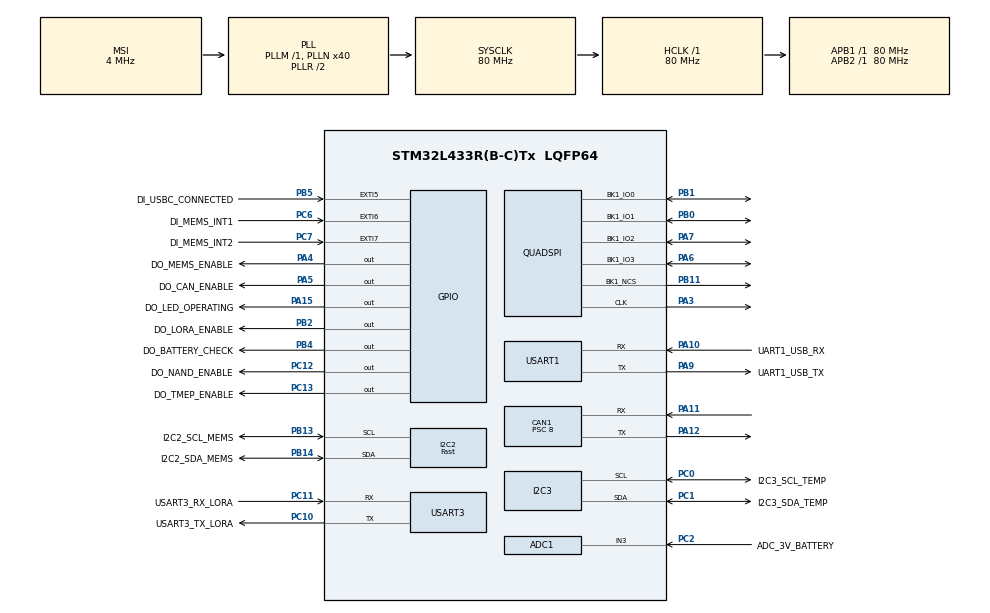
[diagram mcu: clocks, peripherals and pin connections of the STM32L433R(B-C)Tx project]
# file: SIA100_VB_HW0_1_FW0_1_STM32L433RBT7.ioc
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ADC1.ClockPrescaler=ADC_CLOCK_ASYNC_DIV2
ADC1.ContinuousConvMode=DISABLE
ADC1.DMAContinuousRequests=DISABLE
ADC1.EnableRegularConversion=DISABLE
ADC1.master=1
CAN1.ABOM=DISABLE
CAN1.BS1=CAN_BS1_8TQ
CAN1.CalculateBaudRate=1000000
CAN1.CalculateTimeBit=1000
CAN1.CalculateTimeQuantum=100.0
CAN1.Prescaler=8
Dma.Request0=USART1_RX
Dma.Request1=USART3_TX
Dma.Request2=USART3_RX
Dma.USART1_RX.0.Direction=DMA_PERIPH_TO_MEMORY
Dma.USART1_RX.0.Instance=DMA2_Channel7
Dma.USART1_RX.0.MemDataAlignment=DMA_MDATAALIGN_BYTE
Dma.USART1_RX.0.MemInc=DMA_MINC_ENABLE
Dma.USART1_RX.0.Mode=DMA_CIRCULAR
Dma.USART1_RX.0.PeriphDataAlignment=DMA_PDATAALIGN_BYTE
Dma.USART1_RX.0.PeriphInc=DMA_PINC_DISABLE
Dma.USART1_RX.0.Priority=DMA_PRIORITY_LOW
Dma.USART3_RX.2.Direction=DMA_PERIPH_TO_MEMORY
Dma.USART3_RX.2.Instance=DMA1_Channel3
Dma.USART3_RX.2.MemDataAlignment=DMA_MDATAALIGN_BYTE
Dma.USART3_RX.2.MemInc=DMA_MINC_ENABLE
Dma.USART3_RX.2.Mode=DMA_CIRCULAR
Dma.USART3_RX.2.PeriphDataAlignment=DMA_PDATAALIGN_BYTE
Dma.USART3_RX.2.PeriphInc=DMA_PINC_DISABLE
Dma.USART3_RX.2.Priority=DMA_PRIORITY_LOW
Dma.USART3_TX.1.Direction=DMA_MEMORY_TO_PERIPH
Dma.USART3_TX.1.Instance=DMA1_Channel2
Dma.USART3_TX.1.MemDataAlignment=DMA_MDATAALIGN_BYTE
Dma.USART3_TX.1.MemInc=DMA_MINC_ENABLE
Dma.USART3_TX.1.Mode=DMA_NORMAL
Dma.USART3_TX.1.PeriphDataAlignment=DMA_PDATAALIGN_BYTE
Dma.USART3_TX.1.PeriphInc=DMA_PINC_DISABLE
Dma.USART3_TX.1.Priority=DMA_PRIORITY_LOW
I2C2.I2C_Speed_Mode=I2C_Fast
I2C2.Timing=0x00F12981
I2C3.Timing=0x10D19CE4
Mcu.Family=STM32L4
Mcu.Name=STM32L433R(B-C)Tx
Mcu.Package=LQFP64
NVIC.ADC1_IRQn=true\:0\:0\:false\:false\:true\:true\:true\:true
NVIC.CAN1_RX0_IRQn=true\:0\:0\:false\:false\:true\:true\:true\:true
NVIC.CAN1_RX1_IRQn=true\:0\:0\:false\:false\:true\:true\:true\:true
NVIC.DMA1_Channel2_IRQn=true\:0\:0\:false\:false\:true\:false\:true\:true
NVIC.DMA1_Channel3_IRQn=true\:0\:0\:false\:false\:true\:false\:true\:true
NVIC.DMA2_Channel7_IRQn=true\:0\:0\:false\:false\:true\:false\:true\:true
NVIC.EXTI9_5_IRQn=true\:0\:0\:false\:false\:true\:true\:true\:true
NVIC.I2C2_EV_IRQn=true\:0\:0\:false\:false\:true\:true\:true\:true
NVIC.I2C3_EV_IRQn=true\:0\:0\:false\:false\:true\:true\:true\:true
NVIC.PriorityGroup=NVIC_PRIORITYGROUP_4
NVIC.RCC_IRQn=true\:0\:0\:false\:false\:true\:true\:false\:true
NVIC.RTC_WKUP_IRQn=true\:0\:0\:false\:false\:true\:true\:true\:true
NVIC.USART1_IRQn=true\:0\:0\:false\:false\:true\:true\:true\:true
NVIC.USART3_IRQn=true\:0\:0\:false\:false\:true\:true\:true\:true
PA10.GPIO_Label=UART1_USB_RX
PA10.GPIO_PuPd=GPIO_NOPULL
PA10.Mode=Asynchronous
PA10.Signal=USART1_RX
PA11.GPIO_PuPd=GPIO_PULLUP
PA11.Mode=CAN_Activate
PA11.Signal=CAN1_RX
PA12.GPIO_PuPd=GPIO_PULLUP
PA12.Mode=CAN_Activate
PA12.Signal=CAN1_TX
PA13\ (JTMS-SWDIO).Mode=Serial_Wire
PA13\ (JTMS-SWDIO).Signal=SYS_JTMS-SWDIO
PA14\ (JTCK-SWCLK).Mode=Serial_Wire
PA14\ (JTCK-SWCLK).Signal=SYS_JTCK-SWCLK
PA15\ (JTDI).GPIO_Label=DO_LED_OPERATING
PA15\ (JTDI).Signal=GPIO_Output
PA3.GPIO_PuPd=GPIO_NOPULL
PA3.Mode=Single Bank 1
PA3.Signal=QUADSPI_CLK
PA4.GPIO_Label=DO_MEMS_ENABLE
PA4.GPIO_ModeDefaultOutputPP=GPIO_MODE_OUTPUT_OD
PA4.GPIO_PuPd=GPIO_NOPULL
PA4.PinState=GPIO_PIN_SET
PA4.Signal=GPIO_Output
PA5.GPIO_Label=DO_CAN_ENABLE
PA5.GPIO_ModeDefaultOutputPP=GPIO_MODE_OUTPUT_OD
PA5.GPIO_PuPd=GPIO_NOPULL
PA5.PinState=GPIO_PIN_SET
PA5.Signal=GPIO_Output
PA6.GPIO_PuPd=GPIO_NOPULL
PA6.Mode=Single Bank 1
PA6.Signal=QUADSPI_BK1_IO3
PA7.GPIO_PuPd=GPIO_NOPULL
PA7.Mode=Single Bank 1
PA7.Signal=QUADSPI_BK1_IO2
PA9.GPIO_Label=UART1_USB_TX
PA9.GPIO_PuPd=GPIO_NOPULL
PA9.Mode=Asynchronous
PA9.Signal=USART1_TX
PB0.GPIO_PuPd=GPIO_NOPULL
PB0.Mode=Single Bank 1
PB0.Signal=QUADSPI_BK1_IO1
PB1.GPIO_PuPd=GPIO_NOPULL
PB1.Mode=Single Bank 1
PB1.Signal=QUADSPI_BK1_IO0
PB11.GPIO_PuPd=GPIO_NOPULL
PB11.Mode=Single Bank 1
PB11.Signal=QUADSPI_BK1_NCS
PB13.GPIO_Label=I2C2_SCL_MEMS
PB13.GPIO_Pu=GPIO_PULLUP
PB13.Mode=I2C
PB13.Signal=I2C2_SCL
PB14.GPIO_Label=I2C2_SDA_MEMS
PB14.GPIO_Pu=GPIO_PULLUP
PB14.Mode=I2C
PB14.Signal=I2C2_SDA
PB2.GPIO_Label=DO_LORA_ENABLE
PB2.GPIO_ModeDefaultOutputPP=GPIO_MODE_OUTPUT_OD
PB2.GPIO_PuPd=GPIO_NOPULL
PB2.PinState=GPIO_PIN_RESET
PB2.Signal=GPIO_Output
PB4\ (NJTRST).GPIO_Label=DO_BATTERY_CHECK
PB4\ (NJTRST).GPIO_ModeDefaultOutputPP=GPIO_MODE_OUTPUT_OD
PB4\ (NJTRST).GPIO_PuPd=GPIO_NOPULL
PB4\ (NJTRST).PinState=GPIO_PIN_SET
PB4\ (NJTRST).Signal=GPIO_Output
PB5.GPIO_Label=DI_USBC_CONNECTED
PB5.GPIO_PuPd=GPIO_PULLDOWN
PB5.Signal=GPXTI5
PC0.GPIO_Label=I2C3_SCL_TEMP
PC0.GPIO_Pu=GPIO_PULLUP
PC0.Mode=I2C
PC0.Signal=I2C3_SCL
PC1.GPIO_Label=I2C3_SDA_TEMP
PC1.GPIO_Pu=GPIO_PULLUP
PC1.Mode=I2C
PC1.Signal=I2C3_SDA
PC10.GPIO_Label=USART3_TX_LORA
PC10.Mode=Asynchronous
PC10.Signal=USART3_TX
PC11.GPIO_Label=USART3_RX_LORA
PC11.Mode=Asynchronous
PC11.Signal=USART3_RX
PC12.GPIO_Label=DO_NAND_ENABLE
PC12.GPIO_ModeDefaultOutputPP=GPIO_MODE_OUTPUT_OD
PC12.GPIO_PuPd=GPIO_NOPULL
PC12.PinState=GPIO_PIN_SET
PC12.Signal=GPIO_Output
PC13.GPIO_Label=DO_TMEP_ENABLE
PC13.GPIO_ModeDefaultOutputPP=GPIO_MODE_OUTPUT_OD
PC13.GPIO_PuPd=GPIO_NOPULL
PC13.PinState=GPIO_PIN_SET
PC13.Signal=GPIO_Output
PC14-OSC32_IN\ (PC14).Mode=LSE-External-Oscillator
PC14-OSC32_IN\ (PC14).Signal=RCC_OSC32_IN
PC15-OSC32_OUT\ (PC15).Mode=LSE-External-Oscillator
PC15-OSC32_OUT\ (PC15).Signal=RCC_OSC32_OUT
PC2.GPIO_Label=ADC_3V_BATTERY
PC2.Signal=SharedAnalog_PC2
PC6.GPIO_Label=DI_MEMS_INT1
PC6.Signal=GPXTI6
PC7.GPIO_Label=DI_MEMS_INT2
PC7.Signal=GPXTI7
PH0-OSC_IN\ (PH0).Mode=HSE-External-Oscillator
PH0-OSC_IN\ (PH0).Signal=RCC_OSC_IN
PH1-OSC_OUT\ (PH1).Mode=HSE-External-Oscillator
PH1-OSC_OUT\ (PH1).Signal=RCC_OSC_OUT
ProjectManager.HeapSize=0x200
ProjectManager.StackSize=0x400
ProjectManager.TargetToolchain=STM32CubeIDE
QUADSPI.ChipSelectHighTime=QSPI_CS_HIGH_TIME_6_CYCLE
QUADSPI.ClockMode=QSPI_CLOCK_MODE_0
QUADSPI.ClockPrescaler=2
QUADSPI.FifoThreshold=4
QUADSPI.FlashSize=31
QUADSPI.SampleShifting=QSPI_SAMPLE_SHIFTING_HALFCYCLE
RCC.ADCFreq_Value=32000000
RCC.AHBFreq_Value=80000000
RCC.APB1Freq_Value=80000000
RCC.APB1TimFreq_Value=80000000
RCC.APB2Freq_Value=80000000
RCC.APB2TimFreq_Value=80000000
RCC.CortexFreq_Value=80000000
RCC.HCLKFreq_Value=80000000
RCC.HSE_VALUE=16000000
RCC.HSI48_VALUE=48000000
RCC.HSI_VALUE=16000000
RCC.MSI_VALUE=4000000
RCC.PLLN=40
RCC.PLLSAI1N=16
RCC.PWR_Regulator_Voltage_Scale=PWR_REGULATOR_VOLTAGE_SCALE1
RCC.RTCClockSelection=RCC_RTCCLKSOURCE_LSE
RCC.SYSCLKFreq_VALUE=80000000
RCC.SYSCLKSource=RCC_SYSCLKSOURCE_PLLCLK
RCC.USBFreq_Value=32000000
RCC.VCOOutputFreq_Value=160000000
RTC.Format=RTC_FORMAT_BCD
SH.SharedAnalog_PC2.0=GPIO_Analog
SH.SharedAnalog_PC2.1=ADC1_IN3,IN3-Single-Ended
USART1.VirtualMode-Asynchronous=VM_ASYNC
USART3.VirtualMode-Asynchronous=VM_ASYNC
VP_ADC1_Vbat_Input.Mode=IN-Vbat
VP_IWDG_VS_IWDG.Mode=IWDG_Activate
VP_RTC_VS_RTC_Activate.Mode=RTC_Enabled
VP_RTC_VS_RTC_Calendar.Mode=RTC_Calendar
VP_RTC_VS_RTC_WakeUp_intern.Mode=WakeUp
board=custom

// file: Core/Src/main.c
/* USER CODE BEGIN Header */
/**
  ******************************************************************************
  * @file           : main.c
  * @brief          : Main program body
  ******************************************************************************
  * @attention
  *
  * Copyright (c) 2024 STMicroelectronics.
  * All rights reserved.
  *
  * This software is licensed under terms that can be found in the LICENSE file
  * in the root directory of this software component.
  * If no LICENSE file comes with this software, it is provided AS-IS.
  *
  ******************************************************************************
  */
/* USER CODE END Header */
#include "main.h"

/* USER CODE BEGIN Includes */
#include "Mi_Main.h"
/* USER CODE END Includes */

ADC_HandleTypeDef hadc1;

CAN_HandleTypeDef hcan1;

I2C_HandleTypeDef hi2c2;
I2C_HandleTypeDef hi2c3;

IWDG_HandleTypeDef hiwdg;

QSPI_HandleTypeDef hqspi;

RTC_HandleTypeDef hrtc;

UART_HandleTypeDef huart1;
UART_HandleTypeDef huart3;
DMA_HandleTypeDef hdma_usart1_rx;
DMA_HandleTypeDef hdma_usart3_tx;
DMA_HandleTypeDef hdma_usart3_rx;

void SystemClock_Config(void);
static void MX_GPIO_Init(void);
static void MX_DMA_Init(void);
static void MX_CAN1_Init(void);
static void MX_USART1_UART_Init(void);
static void MX_USART3_UART_Init(void);
static void MX_RTC_Init(void);
static void MX_ADC1_Init(void);
static void MX_IWDG_Init(void);
static void MX_QUADSPI_Init(void);
static void MX_I2C2_Init(void);
static void MX_I2C3_Init(void);

int main(void)
{

  /* MCU Configuration--------------------------------------------------------*/

  /* Reset of all peripherals, Initializes the Flash interface and the Systick. */
  HAL_Init();

  /* Configure the system clock */
  SystemClock_Config();

  /* USER CODE BEGIN SysInit */
  DBGMCU->CR &= ~DBGMCU_CR_DBG_STOP;    // 디버깅 중에도 STOP 모드 진입 허용
  __HAL_DBGMCU_FREEZE_RTC();            // 디버깅 중에도 RTC 계속 동작
  /* USER CODE END SysInit */

  /* Initialize all configured peripherals */
  MX_GPIO_Init();
  MX_DMA_Init();
  MX_CAN1_Init();
  MX_USART1_UART_Init();
  MX_USART3_UART_Init();
  MX_RTC_Init();
  MX_ADC1_Init();
  MX_IWDG_Init();
  MX_QUADSPI_Init();
  MX_I2C2_Init();
  MX_I2C3_Init();

  /* Infinite loop */
  while (1)
  {

    /* USER CODE BEGIN 3 */
	  MiMain();
  }
  /* USER CODE END 3 */
}

void SystemClock_Config(void)
{
  RCC_OscInitTypeDef RCC_OscInitStruct = {0};
  RCC_ClkInitTypeDef RCC_ClkInitStruct = {0};

  /** Configure the main internal regulator output voltage
  */
  if (HAL_PWREx_ControlVoltageScaling(PWR_REGULATOR_VOLTAGE_SCALE1) != HAL_OK)
  {
    Error_Handler();
  }

  /** Configure LSE Drive Capability
  */
  HAL_PWR_EnableBkUpAccess();
  __HAL_RCC_LSEDRIVE_CONFIG(RCC_LSEDRIVE_LOW);

  /** Initializes the RCC Oscillators according to the specified parameters
  * in the RCC_OscInitTypeDef structure.
  */
  RCC_OscInitStruct.OscillatorType = RCC_OSCILLATORTYPE_LSI|RCC_OSCILLATORTYPE_LSE
                              |RCC_OSCILLATORTYPE_MSI;
  RCC_OscInitStruct.LSEState = RCC_LSE_ON;
  RCC_OscInitStruct.LSIState = RCC_LSI_ON;
  RCC_OscInitStruct.MSIState = RCC_MSI_ON;
  RCC_OscInitStruct.MSICalibrationValue = 0;
  RCC_OscInitStruct.MSIClockRange = RCC_MSIRANGE_6;
  RCC_OscInitStruct.PLL.PLLState = RCC_PLL_ON;
  RCC_OscInitStruct.PLL.PLLSource = RCC_PLLSOURCE_MSI;
  RCC_OscInitStruct.PLL.PLLM = 1;
  RCC_OscInitStruct.PLL.PLLN = 40;
  RCC_OscInitStruct.PLL.PLLP = RCC_PLLP_DIV7;
  RCC_OscInitStruct.PLL.PLLQ = RCC_PLLQ_DIV2;
  RCC_OscInitStruct.PLL.PLLR = RCC_PLLR_DIV2;
  if (HAL_RCC_OscConfig(&RCC_OscInitStruct) != HAL_OK)
  {
    Error_Handler();
  }

  /** Initializes the CPU, AHB and APB buses clocks
  */
  RCC_ClkInitStruct.ClockType = RCC_CLOCKTYPE_HCLK|RCC_CLOCKTYPE_SYSCLK
                              |RCC_CLOCKTYPE_PCLK1|RCC_CLOCKTYPE_PCLK2;
  RCC_ClkInitStruct.SYSCLKSource = RCC_SYSCLKSOURCE_PLLCLK;
  RCC_ClkInitStruct.AHBCLKDivider = RCC_SYSCLK_DIV1;
  RCC_ClkInitStruct.APB1CLKDivider = RCC_HCLK_DIV1;
  RCC_ClkInitStruct.APB2CLKDivider = RCC_HCLK_DIV1;

  if (HAL_RCC_ClockConfig(&RCC_ClkInitStruct, FLASH_LATENCY_4) != HAL_OK)
  {
    Error_Handler();
  }

  /** Enable MSI Auto calibration
  */
  HAL_RCCEx_EnableMSIPLLMode();
}

static void MX_ADC1_Init(void)
{

  /** Common config
  */
  hadc1.Instance = ADC1;
  hadc1.Init.ClockPrescaler = ADC_CLOCK_ASYNC_DIV2;
  hadc1.Init.Resolution = ADC_RESOLUTION_12B;
  hadc1.Init.DataAlign = ADC_DATAALIGN_RIGHT;
  hadc1.Init.ScanConvMode = ADC_SCAN_DISABLE;
  hadc1.Init.EOCSelection = ADC_EOC_SINGLE_CONV;
  hadc1.Init.LowPowerAutoWait = DISABLE;
  hadc1.Init.ContinuousConvMode = DISABLE;
  hadc1.Init.NbrOfConversion = 1;
  hadc1.Init.DiscontinuousConvMode = DISABLE;
  hadc1.Init.DMAContinuousRequests = DISABLE;
  hadc1.Init.Overrun = ADC_OVR_DATA_PRESERVED;
  hadc1.Init.OversamplingMode = DISABLE;
  if (HAL_ADC_Init(&hadc1) != HAL_OK)
  {
    Error_Handler();
  }

}

static void MX_CAN1_Init(void)
{

  hcan1.Instance = CAN1;
  hcan1.Init.Prescaler = 8;
  hcan1.Init.Mode = CAN_MODE_NORMAL;
  hcan1.Init.SyncJumpWidth = CAN_SJW_1TQ;
  hcan1.Init.TimeSeg1 = CAN_BS1_8TQ;
  hcan1.Init.TimeSeg2 = CAN_BS2_1TQ;
  hcan1.Init.TimeTriggeredMode = DISABLE;
  hcan1.Init.AutoBusOff = DISABLE;
  hcan1.Init.AutoWakeUp = DISABLE;
  hcan1.Init.AutoRetransmission = DISABLE;
  hcan1.Init.ReceiveFifoLocked = DISABLE;
  hcan1.Init.TransmitFifoPriority = DISABLE;
  if (HAL_CAN_Init(&hcan1) != HAL_OK)
  {
    Error_Handler();
  }

}

static void MX_I2C2_Init(void)
{

  hi2c2.Instance = I2C2;
  hi2c2.Init.Timing = 0x00F12981;
  hi2c2.Init.OwnAddress1 = 0;
  hi2c2.Init.AddressingMode = I2C_ADDRESSINGMODE_7BIT;
  hi2c2.Init.DualAddressMode = I2C_DUALADDRESS_DISABLE;
  hi2c2.Init.OwnAddress2 = 0;
  hi2c2.Init.OwnAddress2Masks = I2C_OA2_NOMASK;
  hi2c2.Init.GeneralCallMode = I2C_GENERALCALL_DISABLE;
  hi2c2.Init.NoStretchMode = I2C_NOSTRETCH_DISABLE;
  if (HAL_I2C_Init(&hi2c2) != HAL_OK)
  {
    Error_Handler();
  }

  /** Configure Analogue filter
  */
  if (HAL_I2CEx_ConfigAnalogFilter(&hi2c2, I2C_ANALOGFILTER_ENABLE) != HAL_OK)
  {
    Error_Handler();
  }

  /** Configure Digital filter
  */
  if (HAL_I2CEx_ConfigDigitalFilter(&hi2c2, 0) != HAL_OK)
  {
    Error_Handler();
  }

}

static void MX_I2C3_Init(void)
{

  hi2c3.Instance = I2C3;
  hi2c3.Init.Timing = 0x10D19CE4;
  hi2c3.Init.OwnAddress1 = 0;
  hi2c3.Init.AddressingMode = I2C_ADDRESSINGMODE_7BIT;
  hi2c3.Init.DualAddressMode = I2C_DUALADDRESS_DISABLE;
  hi2c3.Init.OwnAddress2 = 0;
  hi2c3.Init.OwnAddress2Masks = I2C_OA2_NOMASK;
  hi2c3.Init.GeneralCallMode = I2C_GENERALCALL_DISABLE;
  hi2c3.Init.NoStretchMode = I2C_NOSTRETCH_DISABLE;
  if (HAL_I2C_Init(&hi2c3) != HAL_OK)
  {
    Error_Handler();
  }

  /** Configure Analogue filter
  */
  if (HAL_I2CEx_ConfigAnalogFilter(&hi2c3, I2C_ANALOGFILTER_ENABLE) != HAL_OK)
  {
    Error_Handler();
  }

  /** Configure Digital filter
  */
  if (HAL_I2CEx_ConfigDigitalFilter(&hi2c3, 0) != HAL_OK)
  {
    Error_Handler();
  }

}

static void MX_IWDG_Init(void)
{

  hiwdg.Instance = IWDG;
  hiwdg.Init.Prescaler = IWDG_PRESCALER_4;
  hiwdg.Init.Window = 4095;
  hiwdg.Init.Reload = 4095;
  if (HAL_IWDG_Init(&hiwdg) != HAL_OK)
  {
    Error_Handler();
  }

}

static void MX_QUADSPI_Init(void)
{

  /* QUADSPI parameter configuration*/
  hqspi.Instance = QUADSPI;
  hqspi.Init.ClockPrescaler = 2;
  hqspi.Init.FifoThreshold = 4;
  hqspi.Init.SampleShifting = QSPI_SAMPLE_SHIFTING_HALFCYCLE;
  hqspi.Init.FlashSize = 31;
  hqspi.Init.ChipSelectHighTime = QSPI_CS_HIGH_TIME_6_CYCLE;
  hqspi.Init.ClockMode = QSPI_CLOCK_MODE_0;
  hqspi.Init.FlashID = QSPI_FLASH_ID_1;
  hqspi.Init.DualFlash = QSPI_DUALFLASH_DISABLE;
  if (HAL_QSPI_Init(&hqspi) != HAL_OK)
  {
    Error_Handler();
  }

}

static void MX_RTC_Init(void)
{

  RTC_TimeTypeDef sTime = {0};
  RTC_DateTypeDef sDate = {0};

  /** Initialize RTC Only
  */
  hrtc.Instance = RTC;
  hrtc.Init.HourFormat = RTC_HOURFORMAT_24;
  hrtc.Init.AsynchPrediv = 127;
  hrtc.Init.SynchPrediv = 255;
  hrtc.Init.OutPut = RTC_OUTPUT_DISABLE;
  hrtc.Init.OutPutRemap = RTC_OUTPUT_REMAP_NONE;
  hrtc.Init.OutPutPolarity = RTC_OUTPUT_POLARITY_HIGH;
  hrtc.Init.OutPutType = RTC_OUTPUT_TYPE_OPENDRAIN;
  if (HAL_RTC_Init(&hrtc) != HAL_OK)
  {
    Error_Handler();
  }

  /* USER CODE BEGIN Check_RTC_BKUP */
  if(HAL_RTCEx_BKUPRead(&hrtc, RTC_BKP_DR0) == RTC_BACKUPFLAG){
	  return;
  }
  /* USER CODE END Check_RTC_BKUP */

  /** Initialize RTC and set the Time and Date
  */
  sTime.Hours = 0x0;
  sTime.Minutes = 0x0;
  sTime.Seconds = 0x0;
  sTime.DayLightSaving = RTC_DAYLIGHTSAVING_NONE;
  sTime.StoreOperation = RTC_STOREOPERATION_RESET;
  if (HAL_RTC_SetTime(&hrtc, &sTime, RTC_FORMAT_BCD) != HAL_OK)
  {
    Error_Handler();
  }
  sDate.WeekDay = RTC_WEEKDAY_MONDAY;
  sDate.Month = RTC_MONTH_JANUARY;
  sDate.Date = 0x1;
  sDate.Year = 0x0;

  if (HAL_RTC_SetDate(&hrtc, &sDate, RTC_FORMAT_BCD) != HAL_OK)
  {
    Error_Handler();
  }

}

static void MX_USART1_UART_Init(void)
{

  huart1.Instance = USART1;
  huart1.Init.BaudRate = 115200;
  huart1.Init.WordLength = UART_WORDLENGTH_8B;
  huart1.Init.StopBits = UART_STOPBITS_1;
  huart1.Init.Parity = UART_PARITY_NONE;
  huart1.Init.Mode = UART_MODE_TX_RX;
  huart1.Init.HwFlowCtl = UART_HWCONTROL_NONE;
  huart1.Init.OverSampling = UART_OVERSAMPLING_16;
  huart1.Init.OneBitSampling = UART_ONE_BIT_SAMPLE_DISABLE;
  huart1.AdvancedInit.AdvFeatureInit = UART_ADVFEATURE_NO_INIT;
  if (HAL_UART_Init(&huart1) != HAL_OK)
  {
    Error_Handler();
  }
  /* USER CODE BEGIN USART1_Init 2 */
  HAL_UART_DeInit(&huart1);
  /* USER CODE END USART1_Init 2 */

}

static void MX_USART3_UART_Init(void)
{

  huart3.Instance = USART3;
  huart3.Init.BaudRate = 115200;
  huart3.Init.WordLength = UART_WORDLENGTH_8B;
  huart3.Init.StopBits = UART_STOPBITS_1;
  huart3.Init.Parity = UART_PARITY_NONE;
  huart3.Init.Mode = UART_MODE_TX_RX;
  huart3.Init.HwFlowCtl = UART_HWCONTROL_NONE;
  huart3.Init.OverSampling = UART_OVERSAMPLING_16;
  huart3.Init.OneBitSampling = UART_ONE_BIT_SAMPLE_DISABLE;
  huart3.AdvancedInit.AdvFeatureInit = UART_ADVFEATURE_NO_INIT;
  if (HAL_UART_Init(&huart3) != HAL_OK)
  {
    Error_Handler();
  }
  /* USER CODE BEGIN USART3_Init 2 */
  HAL_UART_DeInit(&huart3);
  /* USER CODE END USART3_Init 2 */

}

static void MX_DMA_Init(void)
{

  /* DMA controller clock enable */
  __HAL_RCC_DMA2_CLK_ENABLE();
  __HAL_RCC_DMA1_CLK_ENABLE();

  /* DMA interrupt init */
  /* DMA1_Channel2_IRQn interrupt configuration */
  HAL_NVIC_SetPriority(DMA1_Channel2_IRQn, 0, 0);
  HAL_NVIC_EnableIRQ(DMA1_Channel2_IRQn);
  /* DMA1_Channel3_IRQn interrupt configuration */
  HAL_NVIC_SetPriority(DMA1_Channel3_IRQn, 0, 0);
  HAL_NVIC_EnableIRQ(DMA1_Channel3_IRQn);
  /* DMA2_Channel7_IRQn interrupt configuration */
  HAL_NVIC_SetPriority(DMA2_Channel7_IRQn, 0, 0);
  HAL_NVIC_EnableIRQ(DMA2_Channel7_IRQn);

}

static void MX_GPIO_Init(void)
{
  GPIO_InitTypeDef GPIO_InitStruct = {0};

  /* GPIO Ports Clock Enable */
  __HAL_RCC_GPIOC_CLK_ENABLE();
  __HAL_RCC_GPIOH_CLK_ENABLE();
  __HAL_RCC_GPIOA_CLK_ENABLE();
  __HAL_RCC_GPIOB_CLK_ENABLE();

  /*Configure GPIO pin Output Level */
  HAL_GPIO_WritePin(GPIOC, DO_TMEP_ENABLE_Pin|DO_NAND_ENABLE_Pin, GPIO_PIN_SET);

  /*Configure GPIO pin Output Level */
  HAL_GPIO_WritePin(GPIOA, DO_MEMS_ENABLE_Pin|DO_CAN_ENABLE_Pin, GPIO_PIN_SET);

  /*Configure GPIO pin Output Level */
  HAL_GPIO_WritePin(DO_LORA_ENABLE_GPIO_Port, DO_LORA_ENABLE_Pin, GPIO_PIN_RESET);

  /*Configure GPIO pin Output Level */
  HAL_GPIO_WritePin(DO_LED_OPERATING_GPIO_Port, DO_LED_OPERATING_Pin, GPIO_PIN_RESET);

  /*Configure GPIO pin Output Level */
  HAL_GPIO_WritePin(DO_BATTERY_CHECK_GPIO_Port, DO_BATTERY_CHECK_Pin, GPIO_PIN_SET);

  /*Configure GPIO pins : DO_TMEP_ENABLE_Pin DO_NAND_ENABLE_Pin */
  GPIO_InitStruct.Pin = DO_TMEP_ENABLE_Pin|DO_NAND_ENABLE_Pin;
  GPIO_InitStruct.Mode = GPIO_MODE_OUTPUT_OD;
  GPIO_InitStruct.Pull = GPIO_NOPULL;
  GPIO_InitStruct.Speed = GPIO_SPEED_FREQ_LOW;
  HAL_GPIO_Init(GPIOC, &GPIO_InitStruct);

  /*Configure GPIO pins : DO_MEMS_ENABLE_Pin DO_CAN_ENABLE_Pin */
  GPIO_InitStruct.Pin = DO_MEMS_ENABLE_Pin|DO_CAN_ENABLE_Pin;
  GPIO_InitStruct.Mode = GPIO_MODE_OUTPUT_OD;
  GPIO_InitStruct.Pull = GPIO_NOPULL;
  GPIO_InitStruct.Speed = GPIO_SPEED_FREQ_LOW;
  HAL_GPIO_Init(GPIOA, &GPIO_InitStruct);

  /*Configure GPIO pins : DO_LORA_ENABLE_Pin DO_BATTERY_CHECK_Pin */
  GPIO_InitStruct.Pin = DO_LORA_ENABLE_Pin|DO_BATTERY_CHECK_Pin;
  GPIO_InitStruct.Mode = GPIO_MODE_OUTPUT_OD;
  GPIO_InitStruct.Pull = GPIO_NOPULL;
  GPIO_InitStruct.Speed = GPIO_SPEED_FREQ_LOW;
  HAL_GPIO_Init(GPIOB, &GPIO_InitStruct);

  /*Configure GPIO pins : DI_MEMS_INT1_Pin DI_MEMS_INT2_Pin */
  GPIO_InitStruct.Pin = DI_MEMS_INT1_Pin|DI_MEMS_INT2_Pin;
  GPIO_InitStruct.Mode = GPIO_MODE_IT_RISING;
  GPIO_InitStruct.Pull = GPIO_NOPULL;
  HAL_GPIO_Init(GPIOC, &GPIO_InitStruct);

  /*Configure GPIO pin : DO_LED_OPERATING_Pin */
  GPIO_InitStruct.Pin = DO_LED_OPERATING_Pin;
  GPIO_InitStruct.Mode = GPIO_MODE_OUTPUT_PP;
  GPIO_InitStruct.Pull = GPIO_NOPULL;
  GPIO_InitStruct.Speed = GPIO_SPEED_FREQ_LOW;
  HAL_GPIO_Init(DO_LED_OPERATING_GPIO_Port, &GPIO_InitStruct);

  /*Configure GPIO pin : DI_USBC_CONNECTED_Pin */
  GPIO_InitStruct.Pin = DI_USBC_CONNECTED_Pin;
  GPIO_InitStruct.Mode = GPIO_MODE_IT_RISING;
  GPIO_InitStruct.Pull = GPIO_PULLDOWN;
  HAL_GPIO_Init(DI_USBC_CONNECTED_GPIO_Port, &GPIO_InitStruct);

  /* EXTI interrupt init*/
  HAL_NVIC_SetPriority(EXTI9_5_IRQn, 0, 0);
  HAL_NVIC_EnableIRQ(EXTI9_5_IRQn);

}

void Error_Handler(void)
{
  __disable_irq();
  while (1)
  {
  }
}
